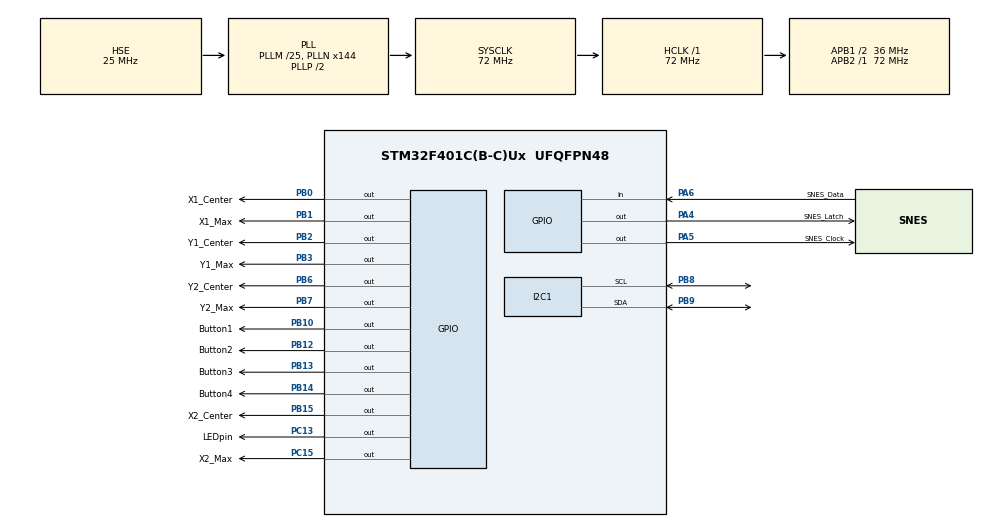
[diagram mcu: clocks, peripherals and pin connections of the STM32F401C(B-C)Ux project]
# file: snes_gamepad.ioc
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Dma.I2C1_RX.0.Direction=DMA_PERIPH_TO_MEMORY
Dma.I2C1_RX.0.FIFOMode=DMA_FIFOMODE_DISABLE
Dma.I2C1_RX.0.Instance=DMA1_Stream0
Dma.I2C1_RX.0.MemDataAlignment=DMA_MDATAALIGN_BYTE
Dma.I2C1_RX.0.MemInc=DMA_MINC_ENABLE
Dma.I2C1_RX.0.Mode=DMA_NORMAL
Dma.I2C1_RX.0.PeriphDataAlignment=DMA_PDATAALIGN_BYTE
Dma.I2C1_RX.0.PeriphInc=DMA_PINC_DISABLE
Dma.I2C1_RX.0.Priority=DMA_PRIORITY_LOW
Dma.I2C1_TX.1.Direction=DMA_MEMORY_TO_PERIPH
Dma.I2C1_TX.1.FIFOMode=DMA_FIFOMODE_DISABLE
Dma.I2C1_TX.1.Instance=DMA1_Stream6
Dma.I2C1_TX.1.MemDataAlignment=DMA_MDATAALIGN_BYTE
Dma.I2C1_TX.1.MemInc=DMA_MINC_ENABLE
Dma.I2C1_TX.1.Mode=DMA_NORMAL
Dma.I2C1_TX.1.PeriphDataAlignment=DMA_PDATAALIGN_BYTE
Dma.I2C1_TX.1.PeriphInc=DMA_PINC_DISABLE
Dma.I2C1_TX.1.Priority=DMA_PRIORITY_LOW
Dma.Request0=I2C1_RX
Dma.Request1=I2C1_TX
FREERTOS.INCLUDE_vTaskDelayUntil=1
FREERTOS.Tasks01=defaultTask,24,128,StartDefaultTask,Default,NULL,Dynamic,NULL,NULL
Mcu.Family=STM32F4
Mcu.Name=STM32F401C(B-C)Ux
Mcu.Package=UFQFPN48
NVIC.DMA1_Stream0_IRQn=true\:5\:0\:false\:false\:true\:true\:false\:true
NVIC.DMA1_Stream6_IRQn=true\:5\:0\:false\:false\:true\:true\:false\:true
NVIC.I2C1_ER_IRQn=true\:5\:0\:false\:false\:true\:true\:true\:true
NVIC.I2C1_EV_IRQn=true\:5\:0\:false\:false\:true\:true\:true\:true
NVIC.PriorityGroup=NVIC_PRIORITYGROUP_4
NVIC.TIM2_IRQn=true\:0\:0\:false\:false\:true\:false\:false\:true
NVIC.TimeBase=TIM2_IRQn
NVIC.TimeBaseIP=TIM2
PA4.GPIO_Label=SNES_Latch
PA4.GPIO_Speed=GPIO_SPEED_FREQ_VERY_HIGH
PA4.Signal=GPIO_Output
PA5.GPIO_Label=SNES_Clock
PA5.GPIO_ModeDefaultOutputPP=GPIO_MODE_OUTPUT_PP
PA5.GPIO_PuPd=GPIO_NOPULL
PA5.GPIO_Speed=GPIO_SPEED_FREQ_VERY_HIGH
PA5.PinState=GPIO_PIN_RESET
PA5.Signal=GPIO_Output
PA6.GPIO_Label=SNES_Data
PA6.GPIO_PuPd=GPIO_PULLUP
PA6.Signal=GPIO_Input
PB0.GPIO_Label=X1_Center
PB0.GPIO_ModeDefaultOutputPP=GPIO_MODE_OUTPUT_OD
PB0.GPIO_PuPd=GPIO_NOPULL
PB0.GPIO_Speed=GPIO_SPEED_FREQ_LOW
PB0.PinState=GPIO_PIN_RESET
PB0.Signal=GPIO_Output
PB1.GPIO_Label=X1_Max
PB1.GPIO_ModeDefaultOutputPP=GPIO_MODE_OUTPUT_OD
PB1.GPIO_PuPd=GPIO_NOPULL
PB1.GPIO_Speed=GPIO_SPEED_FREQ_LOW
PB1.PinState=GPIO_PIN_RESET
PB1.Signal=GPIO_Output
PB10.GPIO_Label=Button1
PB10.GPIO_ModeDefaultOutputPP=GPIO_MODE_OUTPUT_OD
PB10.GPIO_PuPd=GPIO_NOPULL
PB10.GPIO_Speed=GPIO_SPEED_FREQ_LOW
PB10.PinState=GPIO_PIN_RESET
PB10.Signal=GPIO_Output
PB12.GPIO_Label=Button2
PB12.GPIO_ModeDefaultOutputPP=GPIO_MODE_OUTPUT_OD
PB12.Signal=GPIO_Output
PB13.GPIO_Label=Button3
PB13.GPIO_ModeDefaultOutputPP=GPIO_MODE_OUTPUT_OD
PB13.GPIO_PuPd=GPIO_NOPULL
PB13.GPIO_Speed=GPIO_SPEED_FREQ_LOW
PB13.PinState=GPIO_PIN_RESET
PB13.Signal=GPIO_Output
PB14.GPIO_Label=Button4
PB14.GPIO_ModeDefaultOutputPP=GPIO_MODE_OUTPUT_OD
PB14.Signal=GPIO_Output
PB15.GPIO_Label=X2_Center
PB15.GPIO_ModeDefaultOutputPP=GPIO_MODE_OUTPUT_OD
PB15.GPIO_PuPd=GPIO_NOPULL
PB15.Signal=GPIO_Output
PB2.GPIO_Label=Y1_Center
PB2.GPIO_ModeDefaultOutputPP=GPIO_MODE_OUTPUT_OD
PB2.GPIO_PuPd=GPIO_NOPULL
PB2.GPIO_Speed=GPIO_SPEED_FREQ_LOW
PB2.PinState=GPIO_PIN_RESET
PB2.Signal=GPIO_Output
PB3.GPIO_Label=Y1_Max
PB3.GPIO_ModeDefaultOutputPP=GPIO_MODE_OUTPUT_OD
PB3.Signal=GPIO_Output
PB6.GPIO_Label=Y2_Center
PB6.GPIO_ModeDefaultOutputPP=GPIO_MODE_OUTPUT_OD
PB6.GPIO_PuPd=GPIO_NOPULL
PB6.GPIO_Speed=GPIO_SPEED_FREQ_LOW
PB6.PinState=GPIO_PIN_RESET
PB6.Signal=GPIO_Output
PB7.GPIO_Label=Y2_Max
PB7.GPIO_ModeDefaultOutputPP=GPIO_MODE_OUTPUT_OD
PB7.GPIO_PuPd=GPIO_NOPULL
PB7.GPIO_Speed=GPIO_SPEED_FREQ_LOW
PB7.PinState=GPIO_PIN_RESET
PB7.Signal=GPIO_Output
PB8.Mode=I2C
PB8.Signal=I2C1_SCL
PB9.Mode=I2C
PB9.Signal=I2C1_SDA
PC13-ANTI_TAMP.GPIO_Label=LEDpin
PC13-ANTI_TAMP.GPIO_ModeDefaultOutputPP=GPIO_MODE_OUTPUT_OD
PC13-ANTI_TAMP.Signal=GPIO_Output
PC15-OSC32_OUT.GPIO_Label=X2_Max
PC15-OSC32_OUT.GPIO_ModeDefaultOutputPP=GPIO_MODE_OUTPUT_OD
PC15-OSC32_OUT.GPIO_PuPd=GPIO_NOPULL
PC15-OSC32_OUT.Signal=GPIO_Output
PH0\ -\ OSC_IN.Mode=HSE-External-Oscillator
PH0\ -\ OSC_IN.Signal=RCC_OSC_IN
PH1\ -\ OSC_OUT.Mode=HSE-External-Oscillator
PH1\ -\ OSC_OUT.Signal=RCC_OSC_OUT
ProjectManager.HeapSize=0x200
ProjectManager.StackSize=0x400
ProjectManager.TargetToolchain=STM32CubeIDE
RCC.48MHZClocksFreq_Value=28800000
RCC.AHBFreq_Value=72000000
RCC.APB1CLKDivider=RCC_HCLK_DIV2
RCC.APB1Freq_Value=36000000
RCC.APB1TimFreq_Value=72000000
RCC.APB2Freq_Value=72000000
RCC.APB2TimFreq_Value=72000000
RCC.CortexFreq_Value=72000000
RCC.HCLKFreq_Value=72000000
RCC.HSE_VALUE=25000000
RCC.HSI_VALUE=16000000
RCC.LSE_VALUE=32768
RCC.PLLM=25
RCC.PLLN=144
RCC.PLLQ=5
RCC.PLLSourceVirtual=RCC_PLLSOURCE_HSE
RCC.SYSCLKFreq_VALUE=72000000
RCC.SYSCLKSource=RCC_SYSCLKSOURCE_PLLCLK
RCC.VCOOutputFreq_Value=144000000
TIM1.Period=0xffff - 1
TIM1.Prescaler=72-1
VP_FREERTOS_VS_CMSIS_V2.Mode=CMSIS_V2
VP_SYS_VS_tim2.Mode=TIM2
VP_TIM1_VS_ClockSourceINT.Mode=Internal
board=custom

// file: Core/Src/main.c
/* USER CODE BEGIN Header */
/**
  ******************************************************************************
  * @file           : main.c
  * @brief          : Main program body
  ******************************************************************************
  * @attention
  *
  * <h2><center>&copy; Copyright (c) 2021 STMicroelectronics.
  * All rights reserved.</center></h2>
  *
  * This software component is licensed by ST under Ultimate Liberty license
  * SLA0044, the "License"; You may not use this file except in compliance with
  * the License. You may obtain a copy of the License at:
  *                             www.st.com/SLA0044
  *
  ******************************************************************************
  */
/* USER CODE END Header */
#include "main.h"
#include "cmsis_os.h"

/* USER CODE BEGIN Includes */
#include <snestogameport/snesmain.h>
/* USER CODE END Includes */

I2C_HandleTypeDef hi2c1;
DMA_HandleTypeDef hdma_i2c1_rx;
DMA_HandleTypeDef hdma_i2c1_tx;

TIM_HandleTypeDef htim1;

/* Definitions for defaultTask */
osThreadId_t defaultTaskHandle;
const osThreadAttr_t defaultTask_attributes = {
  .name = "defaultTask",
  .priority = (osPriority_t) osPriorityNormal,
  .stack_size = 128 * 4
};

void SystemClock_Config(void);
static void MX_GPIO_Init(void);
static void MX_DMA_Init(void);
static void MX_TIM1_Init(void);
static void MX_I2C1_Init(void);
void StartDefaultTask(void *argument);

int main(void)
{

  /* MCU Configuration--------------------------------------------------------*/

  /* Reset of all peripherals, Initializes the Flash interface and the Systick. */
  HAL_Init();

  /* Configure the system clock */
  SystemClock_Config();

  /* Initialize all configured peripherals */
  MX_GPIO_Init();
  MX_DMA_Init();
  MX_TIM1_Init();
  MX_I2C1_Init();

  /* Init scheduler */
  osKernelInitialize();

  /* Create the thread(s) */
  /* creation of defaultTask */
  defaultTaskHandle = osThreadNew(StartDefaultTask, NULL, &defaultTask_attributes);

  /* Start scheduler */
  osKernelStart();

  /* We should never get here as control is now taken by the scheduler */
  /* Infinite loop */
  while (1)
  {

  }
}

void SystemClock_Config(void)
{
  RCC_OscInitTypeDef RCC_OscInitStruct = {0};
  RCC_ClkInitTypeDef RCC_ClkInitStruct = {0};

  /** Configure the main internal regulator output voltage
  */
  __HAL_RCC_PWR_CLK_ENABLE();
  __HAL_PWR_VOLTAGESCALING_CONFIG(PWR_REGULATOR_VOLTAGE_SCALE2);
  /** Initializes the RCC Oscillators according to the specified parameters
  * in the RCC_OscInitTypeDef structure.
  */
  RCC_OscInitStruct.OscillatorType = RCC_OSCILLATORTYPE_HSE;
  RCC_OscInitStruct.HSEState = RCC_HSE_ON;
  RCC_OscInitStruct.PLL.PLLState = RCC_PLL_ON;
  RCC_OscInitStruct.PLL.PLLSource = RCC_PLLSOURCE_HSE;
  RCC_OscInitStruct.PLL.PLLM = 25;
  RCC_OscInitStruct.PLL.PLLN = 144;
  RCC_OscInitStruct.PLL.PLLP = RCC_PLLP_DIV2;
  RCC_OscInitStruct.PLL.PLLQ = 5;
  if (HAL_RCC_OscConfig(&RCC_OscInitStruct) != HAL_OK)
  {
    Error_Handler();
  }
  /** Initializes the CPU, AHB and APB buses clocks
  */
  RCC_ClkInitStruct.ClockType = RCC_CLOCKTYPE_HCLK|RCC_CLOCKTYPE_SYSCLK
                              |RCC_CLOCKTYPE_PCLK1|RCC_CLOCKTYPE_PCLK2;
  RCC_ClkInitStruct.SYSCLKSource = RCC_SYSCLKSOURCE_PLLCLK;
  RCC_ClkInitStruct.AHBCLKDivider = RCC_SYSCLK_DIV1;
  RCC_ClkInitStruct.APB1CLKDivider = RCC_HCLK_DIV2;
  RCC_ClkInitStruct.APB2CLKDivider = RCC_HCLK_DIV1;

  if (HAL_RCC_ClockConfig(&RCC_ClkInitStruct, FLASH_LATENCY_2) != HAL_OK)
  {
    Error_Handler();
  }
}

static void MX_I2C1_Init(void)
{

  hi2c1.Instance = I2C1;
  hi2c1.Init.ClockSpeed = 100000;
  hi2c1.Init.DutyCycle = I2C_DUTYCYCLE_2;
  hi2c1.Init.OwnAddress1 = 0;
  hi2c1.Init.AddressingMode = I2C_ADDRESSINGMODE_7BIT;
  hi2c1.Init.DualAddressMode = I2C_DUALADDRESS_DISABLE;
  hi2c1.Init.OwnAddress2 = 0;
  hi2c1.Init.GeneralCallMode = I2C_GENERALCALL_DISABLE;
  hi2c1.Init.NoStretchMode = I2C_NOSTRETCH_DISABLE;
  if (HAL_I2C_Init(&hi2c1) != HAL_OK)
  {
    Error_Handler();
  }

}

static void MX_TIM1_Init(void)
{

  TIM_ClockConfigTypeDef sClockSourceConfig = {0};
  TIM_MasterConfigTypeDef sMasterConfig = {0};

  htim1.Instance = TIM1;
  htim1.Init.Prescaler = 72-1;
  htim1.Init.CounterMode = TIM_COUNTERMODE_UP;
  htim1.Init.Period = 0xffff - 1;
  htim1.Init.ClockDivision = TIM_CLOCKDIVISION_DIV1;
  htim1.Init.RepetitionCounter = 0;
  htim1.Init.AutoReloadPreload = TIM_AUTORELOAD_PRELOAD_DISABLE;
  if (HAL_TIM_Base_Init(&htim1) != HAL_OK)
  {
    Error_Handler();
  }
  sClockSourceConfig.ClockSource = TIM_CLOCKSOURCE_INTERNAL;
  if (HAL_TIM_ConfigClockSource(&htim1, &sClockSourceConfig) != HAL_OK)
  {
    Error_Handler();
  }
  sMasterConfig.MasterOutputTrigger = TIM_TRGO_RESET;
  sMasterConfig.MasterSlaveMode = TIM_MASTERSLAVEMODE_DISABLE;
  if (HAL_TIMEx_MasterConfigSynchronization(&htim1, &sMasterConfig) != HAL_OK)
  {
    Error_Handler();
  }

}

static void MX_DMA_Init(void)
{

  /* DMA controller clock enable */
  __HAL_RCC_DMA1_CLK_ENABLE();

  /* DMA interrupt init */
  /* DMA1_Stream0_IRQn interrupt configuration */
  HAL_NVIC_SetPriority(DMA1_Stream0_IRQn, 5, 0);
  HAL_NVIC_EnableIRQ(DMA1_Stream0_IRQn);
  /* DMA1_Stream6_IRQn interrupt configuration */
  HAL_NVIC_SetPriority(DMA1_Stream6_IRQn, 5, 0);
  HAL_NVIC_EnableIRQ(DMA1_Stream6_IRQn);

}

static void MX_GPIO_Init(void)
{
  GPIO_InitTypeDef GPIO_InitStruct = {0};

  /* GPIO Ports Clock Enable */
  __HAL_RCC_GPIOC_CLK_ENABLE();
  __HAL_RCC_GPIOH_CLK_ENABLE();
  __HAL_RCC_GPIOA_CLK_ENABLE();
  __HAL_RCC_GPIOB_CLK_ENABLE();

  /*Configure GPIO pin Output Level */
  HAL_GPIO_WritePin(GPIOC, LEDpin_Pin|X2_Max_Pin, GPIO_PIN_RESET);

  /*Configure GPIO pin Output Level */
  HAL_GPIO_WritePin(GPIOA, SNES_Latch_Pin|SNES_Clock_Pin, GPIO_PIN_RESET);

  /*Configure GPIO pin Output Level */
  HAL_GPIO_WritePin(GPIOB, X1_Center_Pin|X1_Max_Pin|Y1_Center_Pin|Button1_Pin
                          |Button2_Pin|Button3_Pin|Button4_Pin|X2_Center_Pin
                          |Y1_Max_Pin|Y2_Center_Pin|Y2_Max_Pin, GPIO_PIN_RESET);

  /*Configure GPIO pins : LEDpin_Pin X2_Max_Pin */
  GPIO_InitStruct.Pin = LEDpin_Pin|X2_Max_Pin;
  GPIO_InitStruct.Mode = GPIO_MODE_OUTPUT_OD;
  GPIO_InitStruct.Pull = GPIO_NOPULL;
  GPIO_InitStruct.Speed = GPIO_SPEED_FREQ_LOW;
  HAL_GPIO_Init(GPIOC, &GPIO_InitStruct);

  /*Configure GPIO pins : SNES_Latch_Pin SNES_Clock_Pin */
  GPIO_InitStruct.Pin = SNES_Latch_Pin|SNES_Clock_Pin;
  GPIO_InitStruct.Mode = GPIO_MODE_OUTPUT_PP;
  GPIO_InitStruct.Pull = GPIO_NOPULL;
  GPIO_InitStruct.Speed = GPIO_SPEED_FREQ_VERY_HIGH;
  HAL_GPIO_Init(GPIOA, &GPIO_InitStruct);

  /*Configure GPIO pin : SNES_Data_Pin */
  GPIO_InitStruct.Pin = SNES_Data_Pin;
  GPIO_InitStruct.Mode = GPIO_MODE_INPUT;
  GPIO_InitStruct.Pull = GPIO_PULLUP;
  HAL_GPIO_Init(SNES_Data_GPIO_Port, &GPIO_InitStruct);

  /*Configure GPIO pins : X1_Center_Pin X1_Max_Pin Y1_Center_Pin Button1_Pin
                           Button2_Pin Button3_Pin Button4_Pin X2_Center_Pin
                           Y1_Max_Pin Y2_Center_Pin Y2_Max_Pin */
  GPIO_InitStruct.Pin = X1_Center_Pin|X1_Max_Pin|Y1_Center_Pin|Button1_Pin
                          |Button2_Pin|Button3_Pin|Button4_Pin|X2_Center_Pin
                          |Y1_Max_Pin|Y2_Center_Pin|Y2_Max_Pin;
  GPIO_InitStruct.Mode = GPIO_MODE_OUTPUT_OD;
  GPIO_InitStruct.Pull = GPIO_NOPULL;
  GPIO_InitStruct.Speed = GPIO_SPEED_FREQ_LOW;
  HAL_GPIO_Init(GPIOB, &GPIO_InitStruct);

}

void StartDefaultTask(void *argument)
{
  /* USER CODE BEGIN 5 */
  snesMain(&hi2c1,&htim1);
  /* USER CODE END 5 */
}

 /**
  * @brief  Period elapsed callback in non blocking mode
  * @note   This function is called  when TIM2 interrupt took place, inside
  * HAL_TIM_IRQHandler(). It makes a direct call to HAL_IncTick() to increment
  * a global variable "uwTick" used as application time base.
  * @param  htim : TIM handle
  * @retval None
  */
void HAL_TIM_PeriodElapsedCallback(TIM_HandleTypeDef *htim)
{
  if (htim->Instance == TIM2) {
    HAL_IncTick();
  }
}

void Error_Handler(void)
{
  __disable_irq();
  while (1)
  {
  }
}

/************************ (C) COPYRIGHT STMicroelectronics *****END OF FILE****/
